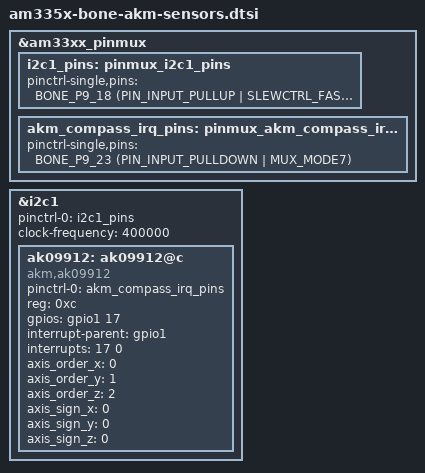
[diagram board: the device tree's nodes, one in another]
/*
 * Copyright (C) 2015 Asahi Kasei Microdevices
 *
 * This program is free software; you can redistribute it and/or modify
 * it under the terms of the GNU General Public License version 2 as
 * published by the Free Software Foundation.
 */

#include <dt-bindings/board/am335x-bbw-bbb-base.h>

&am33xx_pinmux {
	/* i2c */
	i2c1_pins: pinmux_i2c1_pins {
		pinctrl-single,pins = <
			/* spi0_d1.i2c1_sda, SLEWCTRL_SLOW | INPUT_PULLUP | MODE2 */
			BONE_P9_18 (PIN_INPUT_PULLUP | SLEWCTRL_FAST | MUX_MODE2)
			/* spi0_cs0.i2c1_scl, SLEWCTRL_SLOW | INPUT_PULLUP | MODE2 */
			BONE_P9_17 (PIN_INPUT_PULLUP | SLEWCTRL_FAST | MUX_MODE2)
		>;
	};
	akm_compass_irq_pins: pinmux_akm_compass_irq_pins {
		pinctrl-single,pins = <
			/* CAP_TSC gpmc_a1.gpio1_17, INPUT | MODE7 */
			BONE_P9_23 (PIN_INPUT_PULLDOWN | MUX_MODE7)
		>;
	};
};

&i2c1 {
	pinctrl-names = "default";
	pinctrl-0 = <&i2c1_pins>;

	status = "okay";
	clock-frequency = <400000>;

	ak09912: ak09912@c {
		status = "okay";
		compatible = "akm,ak09912";
		pinctrl-names = "default";
		pinctrl-0 = <&akm_compass_irq_pins>;

		reg = <0xc>;
		gpios = <&gpio1 17 0>;
		interrupt-parent = <&gpio1>;
		interrupts = <17 0>;

		axis_order_x = /bits/ 8 <0>;
		axis_order_y = /bits/ 8 <1>;
		axis_order_z = /bits/ 8 <2>;
		axis_sign_x = /bits/ 8 <0>;
		axis_sign_y = /bits/ 8 <0>;
		axis_sign_z = /bits/ 8 <0>;
	};
};

